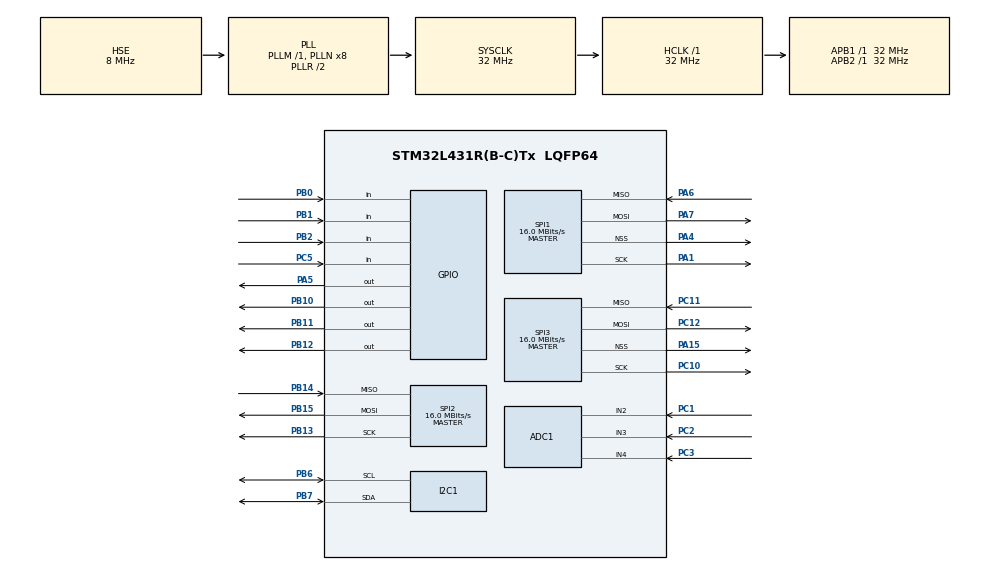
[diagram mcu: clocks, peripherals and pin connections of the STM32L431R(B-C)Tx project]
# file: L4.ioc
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ADC1.Channel-0\#ChannelRegularConversion=ADC_CHANNEL_2
ADC1.EnableAnalogWatchDog1=false
ADC1.NbrOfConversionFlag=1
ADC1.OffsetNumber-0\#ChannelRegularConversion=ADC_OFFSET_NONE
ADC1.Rank-0\#ChannelRegularConversion=1
ADC1.SamplingTime-0\#ChannelRegularConversion=ADC_SAMPLETIME_2CYCLES_5
ADC1.master=1
I2C1.Timing=0x00707CBB
Mcu.Family=STM32L4
Mcu.Name=STM32L431R(B-C)Tx
Mcu.Package=LQFP64
NVIC.PriorityGroup=NVIC_PRIORITYGROUP_4
PA1.Mode=Full_Duplex_Master
PA1.Signal=SPI1_SCK
PA13\ (JTMS-SWDIO).Mode=Serial_Wire
PA13\ (JTMS-SWDIO).Signal=SYS_JTMS-SWDIO
PA14\ (JTCK-SWCLK).Mode=Serial_Wire
PA14\ (JTCK-SWCLK).Signal=SYS_JTCK-SWCLK
PA15\ (JTDI).Mode=NSS_Signal_Hard_Output
PA15\ (JTDI).Signal=SPI3_NSS
PA4.Mode=NSS_Signal_Hard_Output
PA4.Signal=SPI1_NSS
PA5.Signal=GPIO_Output
PA6.Mode=Full_Duplex_Master
PA6.Signal=SPI1_MISO
PA7.Mode=Full_Duplex_Master
PA7.Signal=SPI1_MOSI
PB0.Signal=GPIO_Input
PB1.Signal=GPIO_Input
PB10.GPIO_PuPd=GPIO_PULLUP
PB10.Signal=GPIO_Output
PB11.GPIO_PuPd=GPIO_PULLUP
PB11.GPIO_Speed=GPIO_SPEED_FREQ_LOW
PB11.PinState=GPIO_PIN_RESET
PB11.Signal=GPIO_Output
PB12.GPIO_PuPd=GPIO_PULLUP
PB12.Signal=GPIO_Output
PB13.Mode=Full_Duplex_Master
PB13.Signal=SPI2_SCK
PB14.Mode=Full_Duplex_Master
PB14.Signal=SPI2_MISO
PB15.Mode=Full_Duplex_Master
PB15.Signal=SPI2_MOSI
PB2.Signal=GPIO_Input
PB6.Mode=I2C
PB6.Signal=I2C1_SCL
PB7.Mode=I2C
PB7.Signal=I2C1_SDA
PC1.Signal=ADCx_IN2
PC10.Mode=Full_Duplex_Master
PC10.Signal=SPI3_SCK
PC11.Mode=Full_Duplex_Master
PC11.Signal=SPI3_MISO
PC12.Mode=Full_Duplex_Master
PC12.Signal=SPI3_MOSI
PC14-OSC32_IN\ (PC14).Mode=LSE-External-Oscillator
PC14-OSC32_IN\ (PC14).Signal=RCC_OSC32_IN
PC15-OSC32_OUT\ (PC15).Mode=LSE-External-Oscillator
PC15-OSC32_OUT\ (PC15).Signal=RCC_OSC32_OUT
PC2.Signal=ADCx_IN3
PC3.Signal=ADCx_IN4
PC5.Signal=GPIO_Input
PH0-OSC_IN\ (PH0).Mode=HSE-External-Oscillator
PH0-OSC_IN\ (PH0).Signal=RCC_OSC_IN
PH1-OSC_OUT\ (PH1).Mode=HSE-External-Oscillator
PH1-OSC_OUT\ (PH1).Signal=RCC_OSC_OUT
ProjectManager.HeapSize=0x200
ProjectManager.StackSize=0x400
ProjectManager.TargetToolchain=MDK-ARM V5.32
RCC.ADCFreq_Value=32000000
RCC.AHBFreq_Value=32000000
RCC.APB1Freq_Value=32000000
RCC.APB1TimFreq_Value=32000000
RCC.APB2Freq_Value=32000000
RCC.APB2TimFreq_Value=32000000
RCC.CortexFreq_Value=32000000
RCC.HCLKFreq_Value=32000000
RCC.HSE_VALUE=8000000
RCC.HSI48_VALUE=48000000
RCC.HSI_VALUE=16000000
RCC.MSIClockRange=RCC_MSIRANGE_8
RCC.MSI_VALUE=16000000
RCC.PLLSourceVirtual=RCC_PLLSOURCE_HSE
RCC.SYSCLKFreq_VALUE=32000000
RCC.SYSCLKSource=RCC_SYSCLKSOURCE_PLLCLK
RCC.VCOOutputFreq_Value=64000000
SH.ADCx_IN2.0=ADC1_IN2,IN2-Single-Ended
SH.ADCx_IN3.0=ADC1_IN3,IN3-Single-Ended
SH.ADCx_IN4.0=ADC1_IN4,IN4-Single-Ended
SPI1.CalculateBaudRate=16.0 MBits/s
SPI1.Direction=SPI_DIRECTION_2LINES
SPI1.Mode=SPI_MODE_MASTER
SPI1.VirtualNSS=VM_NSSHARD
SPI1.VirtualType=VM_MASTER
SPI2.CLKPolarity=SPI_POLARITY_HIGH
SPI2.CalculateBaudRate=16.0 MBits/s
SPI2.DataSize=SPI_DATASIZE_8BIT
SPI2.Direction=SPI_DIRECTION_2LINES
SPI2.Mode=SPI_MODE_MASTER
SPI2.VirtualType=VM_MASTER
SPI3.CalculateBaudRate=16.0 MBits/s
SPI3.Direction=SPI_DIRECTION_2LINES
SPI3.Mode=SPI_MODE_MASTER
SPI3.VirtualNSS=VM_NSSHARD
SPI3.VirtualType=VM_MASTER
board=custom

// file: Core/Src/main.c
/* USER CODE BEGIN Header */
/**
  ******************************************************************************
  * @file           : main.c
  * @brief          : Main program body
  ******************************************************************************
  * @attention
  *
  * Copyright (c) 2023 STMicroelectronics.
  * All rights reserved.
  *
  * This software is licensed under terms that can be found in the LICENSE file
  * in the root directory of this software component.
  * If no LICENSE file comes with this software, it is provided AS-IS.
  *
  ******************************************************************************
  */
/* USER CODE END Header */
#include "main.h"
#include "adc.h"
#include "i2c.h"
#include "spi.h"
#include "gpio.h"

/* USER CODE BEGIN Includes */
#include "MainInteract.h"
/* USER CODE END Includes */

void SystemClock_Config(void);

int main(void)
{

  /* MCU Configuration--------------------------------------------------------*/

  /* Reset of all peripherals, Initializes the Flash interface and the Systick. */
  HAL_Init();

  /* Configure the system clock */
  SystemClock_Config();

  /* Initialize all configured peripherals */
  MX_GPIO_Init();
  MX_ADC1_Init();
  MX_I2C1_Init();
  MX_SPI1_Init();
  MX_SPI2_Init();
  MX_SPI3_Init();
  /* USER CODE BEGIN 2 */
 MID_Test();
  /* USER CODE END 2 */

  /* Infinite loop */
  while (1)
  {

  }
}

void SystemClock_Config(void)
{
  RCC_OscInitTypeDef RCC_OscInitStruct = {0};
  RCC_ClkInitTypeDef RCC_ClkInitStruct = {0};

  /** Configure the main internal regulator output voltage
  */
  if (HAL_PWREx_ControlVoltageScaling(PWR_REGULATOR_VOLTAGE_SCALE1) != HAL_OK)
  {
    Error_Handler();
  }

  /** Initializes the RCC Oscillators according to the specified parameters
  * in the RCC_OscInitTypeDef structure.
  */
  RCC_OscInitStruct.OscillatorType = RCC_OSCILLATORTYPE_HSE;
  RCC_OscInitStruct.HSEState = RCC_HSE_ON;
  RCC_OscInitStruct.PLL.PLLState = RCC_PLL_ON;
  RCC_OscInitStruct.PLL.PLLSource = RCC_PLLSOURCE_HSE;
  RCC_OscInitStruct.PLL.PLLM = 1;
  RCC_OscInitStruct.PLL.PLLN = 8;
  RCC_OscInitStruct.PLL.PLLP = RCC_PLLP_DIV7;
  RCC_OscInitStruct.PLL.PLLQ = RCC_PLLQ_DIV2;
  RCC_OscInitStruct.PLL.PLLR = RCC_PLLR_DIV2;
  if (HAL_RCC_OscConfig(&RCC_OscInitStruct) != HAL_OK)
  {
    Error_Handler();
  }

  /** Initializes the CPU, AHB and APB buses clocks
  */
  RCC_ClkInitStruct.ClockType = RCC_CLOCKTYPE_HCLK|RCC_CLOCKTYPE_SYSCLK
                              |RCC_CLOCKTYPE_PCLK1|RCC_CLOCKTYPE_PCLK2;
  RCC_ClkInitStruct.SYSCLKSource = RCC_SYSCLKSOURCE_PLLCLK;
  RCC_ClkInitStruct.AHBCLKDivider = RCC_SYSCLK_DIV1;
  RCC_ClkInitStruct.APB1CLKDivider = RCC_HCLK_DIV1;
  RCC_ClkInitStruct.APB2CLKDivider = RCC_HCLK_DIV1;

  if (HAL_RCC_ClockConfig(&RCC_ClkInitStruct, FLASH_LATENCY_1) != HAL_OK)
  {
    Error_Handler();
  }
}

void Error_Handler(void)
{
  __disable_irq();
  while (1)
  {
  }
}
